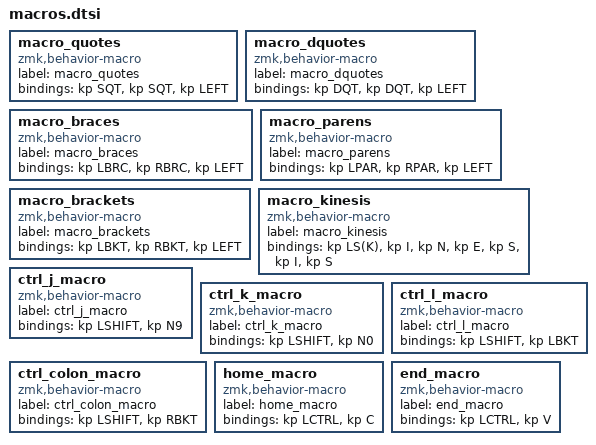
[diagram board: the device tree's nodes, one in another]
macro_quotes: macro_quotes{
compatible = "zmk,behavior-macro";
label = "macro_quotes";
#binding-cells = <0>;
bindings = <&kp SQT>, <&kp SQT>, <&kp LEFT>;
};
macro_dquotes: macro_dquotes{
compatible = "zmk,behavior-macro";
label = "macro_dquotes";
#binding-cells = <0>;
bindings = <&kp DQT>, <&kp DQT>, <&kp LEFT>;
};
macro_braces: macro_braces{
compatible = "zmk,behavior-macro";
label = "macro_braces";
#binding-cells = <0>;
bindings = <&kp LBRC>, <&kp RBRC>, <&kp LEFT>;
};
macro_parens: macro_parens{
compatible = "zmk,behavior-macro";
label = "macro_parens";
#binding-cells = <0>;
bindings = <&kp LPAR>, <&kp RPAR>, <&kp LEFT>;
};
macro_brackets: macro_brackets{
compatible = "zmk,behavior-macro";
label = "macro_brackets";
#binding-cells = <0>;
bindings = <&kp LBKT>, <&kp RBKT>, <&kp LEFT>;
};
macro_kinesis: macro_kinesis{
compatible = "zmk,behavior-macro";
label = "macro_kinesis";
#binding-cells = <0>;
bindings = <&kp LS(K)>, <&kp I>, <&kp N>, <&kp E>, <&kp S>, <&kp I>, <&kp S>;
};
ctrl_j_macro: ctrl_j_macro {
    compatible = "zmk,behavior-macro";
    label = "ctrl_j_macro";
    #binding-cells = <0>;
    bindings = <&kp LSHIFT>, <&kp N9>;  // Shift+9 is (
};
ctrl_k_macro: ctrl_k_macro {
    compatible = "zmk,behavior-macro";
    label = "ctrl_k_macro";
    #binding-cells = <0>;
    bindings = <&kp LSHIFT>, <&kp N0>;  // Shift+0 is )
};
ctrl_l_macro: ctrl_l_macro {
    compatible = "zmk,behavior-macro";
    label = "ctrl_l_macro";
    #binding-cells = <0>;
    bindings = <&kp LSHIFT>, <&kp LBKT>;  // Shift+[ is {
};

ctrl_colon_macro: ctrl_colon_macro {
    compatible = "zmk,behavior-macro";
    label = "ctrl_colon_macro";
    #binding-cells = <0>;
    bindings = <&kp LSHIFT>, <&kp RBKT>;  // Shift+] is }
};
home_macro: home_macro {
    compatible = "zmk,behavior-macro";
    label = "home_macro";
    #binding-cells = <0>;
    bindings = <&kp LCTRL>, <&kp C>;
};
end_macro: end_macro {
    compatible = "zmk,behavior-macro";
    label = "end_macro";
    #binding-cells = <0>;
    bindings = <&kp LCTRL>, <&kp V>;
};
